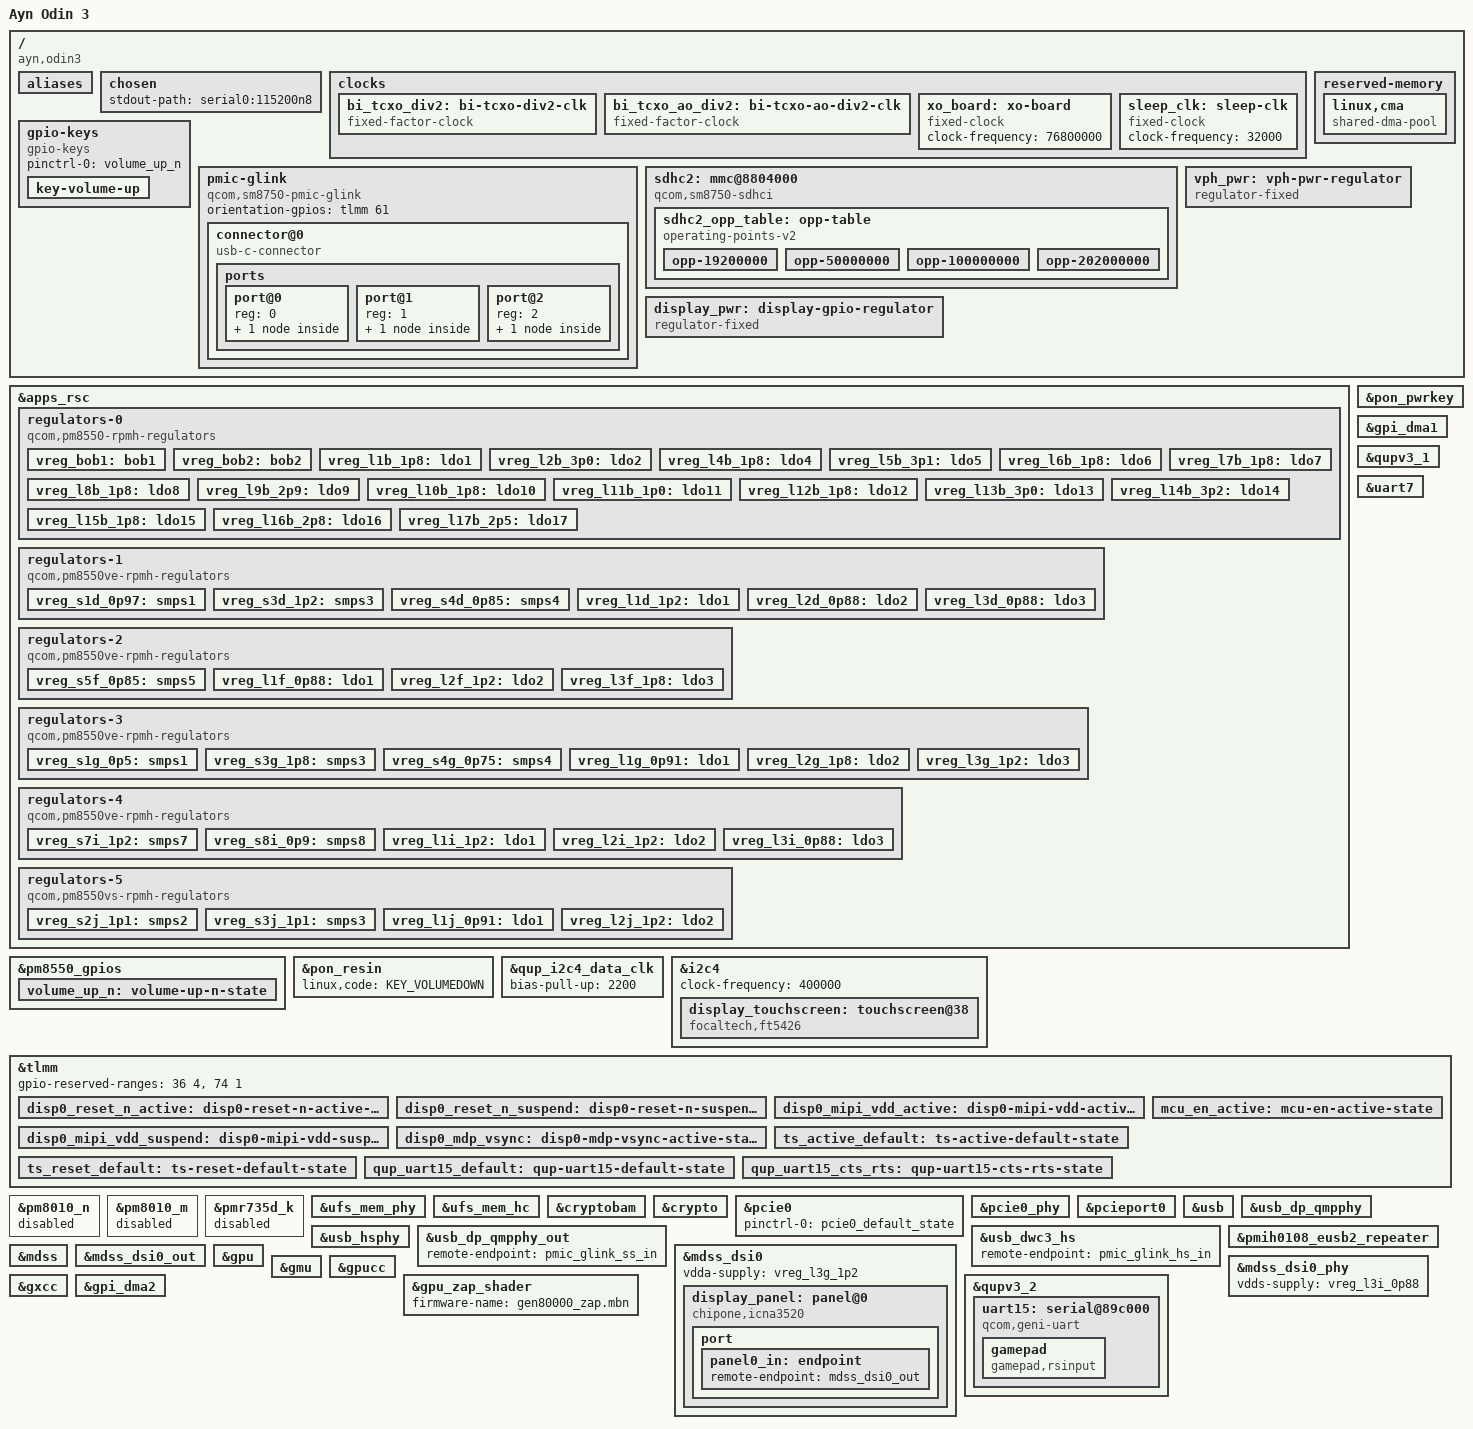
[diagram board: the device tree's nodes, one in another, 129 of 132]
// SPDX-License-Identifier: BSD-3-Clause
/*
 * Copyright (c) 2024 Qualcomm Innovation Center, Inc. All rights reserved.
 * Copyright (c) 2025 gio3k. All rights reserved.
 *
 * Device tree for the Ayn Odin 3, based on the sm8750-mtp dts
 * Takes some inspiration from sm8750-mainline
 */

/dts-v1/;

#include <dt-bindings/gpio/gpio.h>
#include <dt-bindings/leds/common.h>
#include <dt-bindings/regulator/qcom,rpmh-regulator.h>
#include "sm8750.dtsi"
#include "pm8010.dtsi"
#include "pm8550.dtsi"
#define PMK8550VE_SID 8
#include "pm8550ve.dtsi"
#include "pmih0108.dtsi"
#include "pmk8550.dtsi"
#include "pmr735d_a.dtsi"
#include "sm8750-pmics.dtsi"
#include "sm8750-mdss.dtsi"
#include "sm8750-gpu.dtsi"

/ {
	model = "Ayn Odin 3";
	compatible = "ayn,odin3", "qcom,sm8750";
	chassis-type = "handset";

	aliases {
		serial0 = &uart7;
		hsuart1 = &uart15;
	};

	chosen {
		stdout-path = "serial0:115200n8";	

		#address-cells = <2>;
		#size-cells = <2>;
		ranges;
	};

	clocks {
		bi_tcxo_div2: bi-tcxo-div2-clk {
			compatible = "fixed-factor-clock";
			#clock-cells = <0>;

			clocks = <&rpmhcc RPMH_CXO_CLK>;
			clock-mult = <1>;
			clock-div = <2>;
		};

		bi_tcxo_ao_div2: bi-tcxo-ao-div2-clk {
			compatible = "fixed-factor-clock";
			#clock-cells = <0>;

			clocks = <&rpmhcc RPMH_CXO_CLK_A>;
			clock-mult = <1>;
			clock-div = <2>;
		};

		xo_board: xo-board {
			compatible = "fixed-clock";
			clock-frequency = <76800000>;
			#clock-cells = <0>;
		};

		sleep_clk: sleep-clk {
			compatible = "fixed-clock";
			clock-frequency = <32000>;
			#clock-cells = <0>;
		};
	};

	gpio-keys {
		compatible = "gpio-keys";

		pinctrl-0 = <&volume_up_n>;
		pinctrl-names = "default";

		key-volume-up {
			label = "Volume Up";
			linux,code = <KEY_VOLUMEUP>;
			gpios = <&pm8550_gpios 6 GPIO_ACTIVE_LOW>;
			debounce-interval = <15>;
			linux,can-disable;
			wakeup-source;
		};
	};

	reserved-memory {
		#address-cells = <2>;
		#size-cells = <2>;

		linux,cma {
			compatible = "shared-dma-pool";
			size = <0x0 0x8000000>;
			reusable;
			linux,cma-default;
		};
	};

	pmic-glink {
		compatible = "qcom,sm8750-pmic-glink",
			     "qcom,sm8550-pmic-glink",
			     "qcom,pmic-glink";
		
		#address-cells = <1>;
		#size-cells = <0>;
		orientation-gpios = <&tlmm 61 GPIO_ACTIVE_HIGH>;

		connector@0 {
			compatible = "usb-c-connector";
			reg = <0>;
			power-role = "dual";
			data-role = "dual";

			ports {
				#address-cells = <1>;
				#size-cells = <0>;

				port@0 {
					reg = <0>;

					pmic_glink_hs_in: endpoint {
						remote-endpoint = <&usb_dwc3_hs>;
					};
				};

				port@1 {
					reg = <1>;

					pmic_glink_ss_in: endpoint {
						remote-endpoint = <&usb_dp_qmpphy_out>;
					};
				};

				port@2 {
					reg = <2>;

					pmic_glink_sbu: endpoint {};
				};
			};
		};
	};

	sdhc2: mmc@8804000 {
		compatible = "qcom,sm8750-sdhci", "qcom,sdhci-msm-v5";
		reg = <0 0x08804000 0 0x1000>;

		interrupts = <GIC_SPI 207 IRQ_TYPE_LEVEL_HIGH>,
			     <GIC_SPI 223 IRQ_TYPE_LEVEL_HIGH>;
		interrupt-names = "hc_irq", "pwr_irq";

		clocks = <&gcc GCC_SDCC2_AHB_CLK>,
			 <&gcc GCC_SDCC2_APPS_CLK>,
			 <&rpmhcc RPMH_CXO_CLK>;
		clock-names = "iface", "core", "xo";

		power-domains = <&rpmhpd RPMHPD_CX>;
		operating-points-v2 = <&sdhc2_opp_table>;

		interconnects = <&aggre2_noc MASTER_SDCC_2 QCOM_ICC_TAG_ALWAYS
				 &mc_virt SLAVE_EBI1 QCOM_ICC_TAG_ALWAYS>,
				<&gem_noc MASTER_APPSS_PROC QCOM_ICC_TAG_ACTIVE_ONLY
				 &config_noc SLAVE_SDCC_2 QCOM_ICC_TAG_ACTIVE_ONLY>;
		interconnect-names = "sdhc-ddr", "cpu-sdhc";

		iommus = <&apps_smmu 0x540 0>;

		bus-width = <4>;

		dma-coherent;

		sdhc2_opp_table: opp-table {
			compatible = "operating-points-v2";

			opp-19200000 {
				opp-hz = /bits/ 64 <19200000>;
				required-opps = <&rpmhpd_opp_min_svs>;
			};

			opp-50000000 {
				opp-hz = /bits/ 64 <50000000>;
				required-opps = <&rpmhpd_opp_low_svs>;
			};

			opp-100000000 {
				opp-hz = /bits/ 64 <100000000>;
				required-opps = <&rpmhpd_opp_svs>;
			};

			opp-202000000 {
				opp-hz = /bits/ 64 <202000000>;
				required-opps = <&rpmhpd_opp_svs_l1>;
			};
		};
	};

	vph_pwr: vph-pwr-regulator {
		compatible = "regulator-fixed";

		regulator-name = "vph_pwr";
		regulator-min-microvolt = <3600000>;
		regulator-max-microvolt = <3600000>;

		regulator-always-on;
		regulator-boot-on;
	};

	display_pwr: display-gpio-regulator {
		compatible = "regulator-fixed";

		regulator-name = "display_panel_avdd";
		regulator-min-microvolt = <5500000>;
		regulator-max-microvolt = <5500000>;
		regulator-enable-ramp-delay = <233>;

		gpio = <&pm8550_gpios 11 GPIO_ACTIVE_HIGH>;

		enable-active-high;
		regulator-always-on;
		regulator-boot-on;
	};
};

&apps_rsc {
	regulators-0 {
		compatible = "qcom,pm8550-rpmh-regulators";

		vdd-bob1-supply = <&vph_pwr>;
		vdd-bob2-supply = <&vph_pwr>;
		vdd-l1-l4-l10-supply = <&vreg_s3g_1p8>;
		vdd-l2-l13-l14-supply = <&vreg_bob1>;
		vdd-l3-supply = <&vreg_s7i_1p2>;
		vdd-l5-l16-supply = <&vreg_bob1>;
		vdd-l6-l7-supply = <&vreg_bob1>;
		vdd-l8-l9-supply = <&vreg_bob1>;
		vdd-l11-supply = <&vreg_s7i_1p2>;
		vdd-l12-supply = <&vreg_s3g_1p8>;
		vdd-l15-supply = <&vreg_s3g_1p8>;
		vdd-l17-supply = <&vreg_bob2>;

		qcom,pmic-id = "b";

		// RPMH_REGULATOR_MODE_RET = 1 in DTB (0 in header)
		// RPMH_REGULATOR_MODE_LPM = 2 in DTB
		// RPMH_REGULATOR_MODE_AUTO = 3 in DTB
		// RPMH_REGULATOR_MODE_HPM = 4 in DTB

		// rpmh-regulator-bobb1/regulator-pm-humu-bob1
		vreg_bob1: bob1 {
			// pm_humu_bob1
			regulator-name = "vreg_bob1";
			regulator-min-microvolt = <3008000>;
			regulator-max-microvolt = <4000000>;
			regulator-initial-mode = <RPMH_REGULATOR_MODE_HPM>;
		};

		// rpmh-regulator-bobb2/regulator-pm-humu-bob2
		vreg_bob2: bob2 {
			regulator-name = "vreg_bob2";
			regulator-min-microvolt = <2704000>;
			regulator-max-microvolt = <3008000>;
			regulator-initial-mode = <RPMH_REGULATOR_MODE_HPM>;
		};

		// rpmh-regulator-ldob1/regulator-pm-humu-l1
		vreg_l1b_1p8: ldo1 {
			// pm_humu_l1
			regulator-name = "vreg_l1b_1p8";
			regulator-min-microvolt = <1800000>;
			regulator-max-microvolt = <1800000>;
			regulator-initial-mode = <RPMH_REGULATOR_MODE_HPM>;
			regulator-allow-set-load;
			regulator-allowed-modes = <RPMH_REGULATOR_MODE_LPM RPMH_REGULATOR_MODE_HPM>;
		};

		// rpmh-regulator-ldob2/regulator-pm-humu-l2
		vreg_l2b_3p0: ldo2 {
			regulator-name = "vreg_l2b_3p0";
			regulator-min-microvolt = <3008000>;
			regulator-max-microvolt = <3048000>;
			regulator-initial-mode = <RPMH_REGULATOR_MODE_HPM>;
			regulator-allow-set-load;
			regulator-allowed-modes = <RPMH_REGULATOR_MODE_LPM RPMH_REGULATOR_MODE_HPM>;
		};

		// rpmh-regulator-ldob4/regulator-pm-humu-l4
		vreg_l4b_1p8: ldo4 {
			regulator-name = "vreg_l4b_1p8";
			regulator-min-microvolt = <1800000>;
			regulator-max-microvolt = <1800000>;
			regulator-initial-mode = <RPMH_REGULATOR_MODE_HPM>;
			regulator-allow-set-load;
			regulator-allowed-modes = <RPMH_REGULATOR_MODE_LPM RPMH_REGULATOR_MODE_HPM>;
		};

		// rpmh-regulator-ldob5/regulator-pm-humu-l5
		vreg_l5b_3p1: ldo5 {
			regulator-name = "vreg_l5b_3p1";
			regulator-min-microvolt = <3100000>;
			regulator-max-microvolt = <3148000>;
			regulator-initial-mode = <RPMH_REGULATOR_MODE_HPM>;
			regulator-allow-set-load;
			regulator-allowed-modes = <RPMH_REGULATOR_MODE_LPM RPMH_REGULATOR_MODE_HPM>;
		};

		// rpmh-regulator-ldob6/regulator-pm-humu-l6
		vreg_l6b_1p8: ldo6 {
			regulator-name = "vreg_l6b_1p8";
			regulator-min-microvolt = <1800000>;
			regulator-max-microvolt = <3008000>;
			regulator-initial-mode = <RPMH_REGULATOR_MODE_HPM>;
			regulator-allow-set-load;
			regulator-allowed-modes = <RPMH_REGULATOR_MODE_LPM RPMH_REGULATOR_MODE_HPM>;
		};

		// rpmh-regulator-ldob7/regulator-pm-humu-l7
		vreg_l7b_1p8: ldo7 {
			regulator-name = "vreg_l7b_1p8";
			regulator-min-microvolt = <1800000>;
			regulator-max-microvolt = <3008000>;
			regulator-initial-mode = <RPMH_REGULATOR_MODE_HPM>;
			regulator-allow-set-load;
			regulator-allowed-modes = <RPMH_REGULATOR_MODE_LPM RPMH_REGULATOR_MODE_HPM>;
		};

		// rpmh-regulator-ldob8/regulator-pm-humu-l8
		vreg_l8b_1p8: ldo8 {
			regulator-name = "vreg_l8b_1p8";
			regulator-min-microvolt = <1800000>;
			regulator-max-microvolt = <3008000>;
			regulator-initial-mode = <RPMH_REGULATOR_MODE_HPM>;
			regulator-allow-set-load;
			regulator-allowed-modes = <RPMH_REGULATOR_MODE_LPM RPMH_REGULATOR_MODE_HPM>;
		};

		// rpmh-regulator-ldob9/regulator-pm-humu-l9
		vreg_l9b_2p9: ldo9 {
			regulator-name = "vreg_l9b_2p9";
			regulator-min-microvolt = <2960000>;
			regulator-max-microvolt = <3008000>;
			regulator-initial-mode = <RPMH_REGULATOR_MODE_HPM>;
			regulator-allow-set-load;
			regulator-allowed-modes = <RPMH_REGULATOR_MODE_LPM RPMH_REGULATOR_MODE_HPM>;
		};

		// rpmh-regulator-ldob10/regulator-pm-humu-l10
		vreg_l10b_1p8: ldo10 {
			regulator-name = "vreg_l10b_1p8";
			regulator-min-microvolt = <1800000>;
			regulator-max-microvolt = <1800000>;
			regulator-initial-mode = <RPMH_REGULATOR_MODE_HPM>;
			regulator-allow-set-load;
			regulator-allowed-modes = <RPMH_REGULATOR_MODE_LPM RPMH_REGULATOR_MODE_HPM>;
		};

		// rpmh-regulator-ldob11/regulator-pm-humu-l11
		vreg_l11b_1p0: ldo11 {
			regulator-name = "vreg_l11b_1p0";
			regulator-min-microvolt = <1064000>;
			regulator-max-microvolt = <1292000>;
			regulator-initial-mode = <RPMH_REGULATOR_MODE_HPM>;
			regulator-allow-set-load;
			regulator-allowed-modes = <RPMH_REGULATOR_MODE_LPM RPMH_REGULATOR_MODE_HPM>;
		};

		// rpmh-regulator-ldob12/regulator-pm-humu-l12
		vreg_l12b_1p8: ldo12 {
			regulator-name = "vreg_l12b_1p8";
			regulator-min-microvolt = <1800000>;
			regulator-max-microvolt = <1800000>;
			regulator-initial-mode = <RPMH_REGULATOR_MODE_HPM>;
			regulator-allow-set-load;
			regulator-allowed-modes = <RPMH_REGULATOR_MODE_LPM RPMH_REGULATOR_MODE_HPM>;
			regulator-always-on;
		};

		// rpmh-regulator-ldob13/regulator-pm-humu-l13
		vreg_l13b_3p0: ldo13 {
			regulator-name = "vreg_l13b_3p0";
			regulator-min-microvolt = <3000000>;
			regulator-max-microvolt = <3000000>;
			regulator-initial-mode = <RPMH_REGULATOR_MODE_HPM>;
			regulator-allow-set-load;
			regulator-allowed-modes = <RPMH_REGULATOR_MODE_LPM RPMH_REGULATOR_MODE_HPM>;
		};

		// rpmh-regulator-ldob14/regulator-pm-humu-l14
		vreg_l14b_3p2: ldo14 {
			regulator-name = "vreg_l14b_3p2";
			regulator-min-microvolt = <3200000>;
			regulator-max-microvolt = <3200000>;
			regulator-initial-mode = <RPMH_REGULATOR_MODE_HPM>;
			regulator-allow-set-load;
			regulator-allowed-modes = <RPMH_REGULATOR_MODE_LPM RPMH_REGULATOR_MODE_HPM>;
		};

		// rpmh-regulator-ldob15/regulator-pm-humu-l15
		vreg_l15b_1p8: ldo15 {
			regulator-name = "vreg_l15b_1p8";
			regulator-min-microvolt = <1800000>;
			regulator-max-microvolt = <1800000>;
			regulator-initial-mode = <RPMH_REGULATOR_MODE_HPM>;
			regulator-allow-set-load;
			regulator-allowed-modes = <RPMH_REGULATOR_MODE_LPM RPMH_REGULATOR_MODE_HPM>;
			regulator-always-on;
		};

		// rpmh-regulator-ldob16/regulator-pm-humu-l16
		vreg_l16b_2p8: ldo16 {
			regulator-name = "vreg_l16b_2p8";
			regulator-min-microvolt = <2800000>;
			regulator-max-microvolt = <2800000>;
			regulator-initial-mode = <RPMH_REGULATOR_MODE_HPM>;
			regulator-allow-set-load;
			regulator-allowed-modes = <RPMH_REGULATOR_MODE_LPM RPMH_REGULATOR_MODE_HPM>;
		};

		// rpmh-regulator-ldob17/regulator-pm-humu-l17
		vreg_l17b_2p5: ldo17 {
			regulator-name = "vreg_l17b_2p5";
			regulator-min-microvolt = <2504000>;
			regulator-max-microvolt = <2504000>;
			regulator-initial-mode = <RPMH_REGULATOR_MODE_HPM>;
			regulator-allow-set-load;
			regulator-allowed-modes = <RPMH_REGULATOR_MODE_LPM RPMH_REGULATOR_MODE_HPM>;
		};
	};

	regulators-1 {
		compatible = "qcom,pm8550ve-rpmh-regulators";

		vdd-l1-supply = <&vreg_s7i_1p2>;
		vdd-l2-supply = <&vreg_s1d_0p97>;
		vdd-l3-supply = <&vreg_s1d_0p97>;
		vdd-s1-supply = <&vph_pwr>;
		vdd-s3-supply = <&vph_pwr>;
		vdd-s4-supply = <&vph_pwr>;

		qcom,pmic-id = "d";

		// rpmh-regulator-smpd1/regulator-pm-v8d-s1
		vreg_s1d_0p97: smps1 {
			regulator-name = "vreg_s1d_0p97";
			regulator-min-microvolt = <880000>;
			regulator-max-microvolt = <1100000>;
			regulator-initial-mode = <RPMH_REGULATOR_MODE_HPM>;
		};

		// rpmh-regulator-smpd3/regulator-pm-v8d-s3
		vreg_s3d_1p2: smps3 {
			regulator-name = "vreg_s3d_1p2";
			regulator-min-microvolt = <1200000>;
			regulator-max-microvolt = <1300000>;
			regulator-initial-mode = <RPMH_REGULATOR_MODE_HPM>;
		};

		// rpmh-regulator-smpd4/regulator-pm-v8d-s4
		vreg_s4d_0p85: smps4 {
			regulator-name = "vreg_s4d_0p85";
			regulator-min-microvolt = <500000>;
			regulator-max-microvolt = <1036000>;
			regulator-initial-mode = <RPMH_REGULATOR_MODE_HPM>;
		};

		// rpmh-regulator-ldod1/regulator-pm-v8d-l1
		vreg_l1d_1p2: ldo1 {
			regulator-name = "vreg_l1d_1p2";
			regulator-min-microvolt = <1200000>;
			regulator-max-microvolt = <1200000>;
			regulator-initial-mode = <RPMH_REGULATOR_MODE_HPM>;
			regulator-allow-set-load;
			regulator-allowed-modes = <RPMH_REGULATOR_MODE_LPM RPMH_REGULATOR_MODE_HPM>;
		};

		// rpmh-regulator-ldod2/regulator-pm-v8d-l2
		vreg_l2d_0p88: ldo2 {
			regulator-name = "vreg_l2d_0p88";
			regulator-min-microvolt = <880000>;
			regulator-max-microvolt = <912000>;
			regulator-initial-mode = <RPMH_REGULATOR_MODE_HPM>;
			regulator-allow-set-load;
			regulator-allowed-modes = <RPMH_REGULATOR_MODE_LPM RPMH_REGULATOR_MODE_HPM>;
		};

		// rpmh-regulator-ldod3/regulator-pm-v8d-l3
		vreg_l3d_0p88: ldo3 {
			regulator-name = "vreg_l3d_0p88";
			regulator-min-microvolt = <880000>;
			regulator-max-microvolt = <920000>;
			regulator-initial-mode = <RPMH_REGULATOR_MODE_HPM>;
			regulator-allow-set-load;
			regulator-allowed-modes = <RPMH_REGULATOR_MODE_LPM RPMH_REGULATOR_MODE_HPM>;
		};
	};

	regulators-2 {
		compatible = "qcom,pm8550ve-rpmh-regulators";

		vdd-l1-supply = <&vreg_s1d_0p97>;
		vdd-l2-supply = <&vreg_s7i_1p2>;
		vdd-l3-supply = <&vreg_s3g_1p8>;
		vdd-s5-supply = <&vph_pwr>;

		qcom,pmic-id = "f";

		// rpmh-regulator-smpf5/regulator-pm-v8f-s5
		vreg_s5f_0p85: smps5 {
			regulator-name = "vreg_s5f_0p85";
			regulator-min-microvolt = <500000>;
			regulator-max-microvolt = <1000000>;
			regulator-initial-mode = <RPMH_REGULATOR_MODE_HPM>;
		};

		// rpmh-regulator-ldof1/regulator-pm-vxf-l1
		// todo: -ao & -so
		vreg_l1f_0p88: ldo1 {
			regulator-name = "vreg_l1f_0p88";
			regulator-min-microvolt = <880000>;
			regulator-max-microvolt = <920000>;
			regulator-initial-mode = <RPMH_REGULATOR_MODE_HPM>;
			regulator-allow-set-load;
			regulator-allowed-modes = <RPMH_REGULATOR_MODE_LPM RPMH_REGULATOR_MODE_HPM>;
		};

		// rpmh-regulator-ldof2/regulator-pm-vxf-l2
		vreg_l2f_1p2: ldo2 {
			regulator-name = "vreg_l2f_1p2";
			regulator-min-microvolt = <1200000>;
			regulator-max-microvolt = <1200000>;
			regulator-initial-mode = <RPMH_REGULATOR_MODE_HPM>;
			regulator-allow-set-load;
			regulator-allowed-modes = <RPMH_REGULATOR_MODE_LPM RPMH_REGULATOR_MODE_HPM>;
		};

		// rpmh-regulator-ldof3/regulator-pm-vxf-l3
		vreg_l3f_1p8: ldo3 {
			regulator-name = "vreg_l3f_1p8";
			regulator-min-microvolt = <1800000>;
			regulator-max-microvolt = <1800000>;
			regulator-initial-mode = <RPMH_REGULATOR_MODE_HPM>;
			regulator-allow-set-load;
			regulator-allowed-modes = <RPMH_REGULATOR_MODE_LPM RPMH_REGULATOR_MODE_HPM>;
		};
	};

	regulators-3 {
		compatible = "qcom,pm8550ve-rpmh-regulators";

		vdd-l1-supply = <&vreg_s1d_0p97>;
		vdd-l2-supply = <&vreg_s3g_1p8>;
		vdd-l3-supply = <&vreg_s7i_1p2>;
		vdd-s1-supply = <&vph_pwr>;
		vdd-s3-supply = <&vph_pwr>;

		qcom,pmic-id = "g";

		// rpmh-regulator-smpg1/regulator-pm-v8g-s1
		vreg_s1g_0p5: smps1 {
			regulator-name = "vreg_s1g_0p5";
			regulator-min-microvolt = <300000>;
			regulator-max-microvolt = <700000>;
			regulator-initial-mode = <RPMH_REGULATOR_MODE_HPM>;
		};

		// rpmh-regulator-smpg3/regulator-pm-v8g-s3
		vreg_s3g_1p8: smps3 {
			regulator-name = "vreg_s3g_1p8";
			regulator-min-microvolt = <1856000>;
			regulator-max-microvolt = <2000000>;
			regulator-initial-mode = <RPMH_REGULATOR_MODE_LPM>;
			regulator-allow-set-load;
			regulator-allowed-modes = <RPMH_REGULATOR_MODE_LPM RPMH_REGULATOR_MODE_HPM>;
		};

		// rpmh-regulator-smpg4/regulator-pm-v8g-s4
		vreg_s4g_0p75: smps4 {
			regulator-name = "vreg_s4g_0p75";
			regulator-min-microvolt = <300000>;
			regulator-max-microvolt = <900000>;
			regulator-initial-mode = <RPMH_REGULATOR_MODE_HPM>;
		};

		// rpmh-regulator-ldog1/regulator-pm-v8g-l1
		vreg_l1g_0p91: ldo1 {
			regulator-name = "vreg_l1g_0p91";
			regulator-min-microvolt = <912000>;
			regulator-max-microvolt = <936000>;
			regulator-initial-mode = <RPMH_REGULATOR_MODE_HPM>;
			regulator-allow-set-load;
			regulator-allowed-modes = <RPMH_REGULATOR_MODE_LPM RPMH_REGULATOR_MODE_HPM>;
		};

		// rpmh-regulator-ldog2/regulator-pm-v8g-s2
		vreg_l2g_1p8: ldo2 {
			regulator-name = "vreg_l2g_1p8";
			regulator-min-microvolt = <1200000>;
			regulator-max-microvolt = <1860000>;
			regulator-initial-mode = <RPMH_REGULATOR_MODE_HPM>;
			regulator-allow-set-load;
			regulator-allowed-modes = <RPMH_REGULATOR_MODE_LPM RPMH_REGULATOR_MODE_HPM>;
		};

		// rpmh-regulator-ldog3/regulator-pm-v8g-l3
		vreg_l3g_1p2: ldo3 {
			regulator-name = "vreg_l3g_1p2";
			regulator-min-microvolt = <1200000>;
			regulator-max-microvolt = <1256000>;
			regulator-initial-mode = <RPMH_REGULATOR_MODE_HPM>;
			regulator-allow-set-load;
			regulator-allowed-modes = <RPMH_REGULATOR_MODE_LPM RPMH_REGULATOR_MODE_HPM>;
		};
	};

	regulators-4 {
		compatible = "qcom,pm8550ve-rpmh-regulators";

		vdd-l1-supply = <&vreg_s7i_1p2>;
		vdd-l2-supply = <&vreg_s7i_1p2>;
		vdd-l3-supply = <&vreg_s1d_0p97>;
		vdd-s7-supply = <&vph_pwr>;
		vdd-s8-supply = <&vph_pwr>;

		qcom,pmic-id = "i";

		// rpmh-regulator-smpi7/regulator-pm-v8i-s7
		vreg_s7i_1p2: smps7 {
			regulator-name = "vreg_s7i_1p2";
			regulator-min-microvolt = <1224000>;
			regulator-max-microvolt = <1340000>;
			regulator-initial-mode = <RPMH_REGULATOR_MODE_HPM>;
		};

		// rpmh-regulator-smpi8/regulator-pm-v8i-s8
		vreg_s8i_0p9: smps8 {
			regulator-name = "vreg_s8i_0p9";
			regulator-min-microvolt = <900000>;
			regulator-max-microvolt = <972000>;
			regulator-initial-mode = <RPMH_REGULATOR_MODE_HPM>;
		};

		// rpmh-regulator-ldoi1/regulator-pm-v8i-l1
		vreg_l1i_1p2: ldo1 {
			regulator-name = "vreg_l1i_1p2";
			regulator-min-microvolt = <1200000>;
			regulator-max-microvolt = <1200000>;
			regulator-initial-mode = <RPMH_REGULATOR_MODE_HPM>;
			regulator-allow-set-load;
			regulator-allowed-modes = <RPMH_REGULATOR_MODE_LPM RPMH_REGULATOR_MODE_HPM>;
		};

		// rpmh-regulator-ldoi2/regulator-pm-v8i-l2
		vreg_l2i_1p2: ldo2 {
			regulator-name = "vreg_l2i_1p2";
			regulator-min-microvolt = <1200000>;
			regulator-max-microvolt = <1200000>;
			regulator-initial-mode = <RPMH_REGULATOR_MODE_HPM>;
			regulator-allow-set-load;
			regulator-allowed-modes = <RPMH_REGULATOR_MODE_LPM RPMH_REGULATOR_MODE_HPM>;
		};

		// rpmh-regulator-ldoi3/regulator-pm-v8i-l3
		vreg_l3i_0p88: ldo3 {
			regulator-name = "vreg_l3i_0p88";
			regulator-min-microvolt = <880000>;
			regulator-max-microvolt = <912000>;
			regulator-initial-mode = <RPMH_REGULATOR_MODE_HPM>;
			regulator-allow-set-load;
			regulator-allowed-modes = <RPMH_REGULATOR_MODE_LPM RPMH_REGULATOR_MODE_HPM>;
		};
	};

	regulators-5 {
		compatible = "qcom,pm8550vs-rpmh-regulators";

		vdd-l1-supply = <&vreg_s1d_0p97>;
		vdd-l2-supply = <&vreg_s7i_1p2>;
		vdd-s2-supply = <&vph_pwr>;
		vdd-s3-supply = <&vph_pwr>;

		qcom,pmic-id = "j";

		// rpmh-regulator-smpj2/regulator-pm-v6j-s2
		vreg_s2j_1p1: smps2 {
			regulator-name = "vreg_s2j_1p1";
			regulator-min-microvolt = <1000000>;
			regulator-max-microvolt = <1100000>;
			regulator-initial-mode = <RPMH_REGULATOR_MODE_HPM>;
		};

		// rpmh-regulator-smpj3/regulator-pm-v6j-s3
		vreg_s3j_1p1: smps3 {
			regulator-name = "vreg_s3j_1p1";
			regulator-min-microvolt = <1000000>;
			regulator-max-microvolt = <1100000>;
			regulator-initial-mode = <RPMH_REGULATOR_MODE_HPM>;
		};

		// rpmh-regulator-ldoj1/regulator-pm-v6j-l1
		vreg_l1j_0p91: ldo1 {
			regulator-name = "vreg_l1j_0p91";
			regulator-min-microvolt = <880000>;
			regulator-max-microvolt = <920000>;
			regulator-initial-mode = <RPMH_REGULATOR_MODE_HPM>;
			regulator-allow-set-load;
			regulator-allowed-modes = <RPMH_REGULATOR_MODE_LPM RPMH_REGULATOR_MODE_HPM>;
		};

		// rpmh-regulator-ldoj2/regulator-pm-v6j-l2
		vreg_l2j_1p2: ldo2 {
			regulator-name = "vreg_l2j_1p2";
			regulator-min-microvolt = <1200000>;
			regulator-max-microvolt = <1200000>;
			regulator-initial-mode = <RPMH_REGULATOR_MODE_HPM>;
			regulator-allow-set-load;
			regulator-allowed-modes = <RPMH_REGULATOR_MODE_LPM RPMH_REGULATOR_MODE_HPM>;
		};
	};
};

/* Power & volume keys */
&pm8550_gpios {
	volume_up_n: volume-up-n-state {
		pins = "gpio6";
		function = "normal";
		input-enable;
		bias-pull-up;
		power-source = <1>;
	};
};

&pon_pwrkey {
	status = "okay";
};

&pon_resin {
	status = "okay";

	linux,code = <KEY_VOLUMEDOWN>;
};

// I2C through QUPv3_1
&gpi_dma1 {
	status = "okay";
};

&qupv3_1 {
	status = "okay";
};

&uart7 {
	status = "okay";
};

&qup_i2c4_data_clk {
	/* Use internal I2C pull-up */
	bias-pull-up = <2200>;
};

&i2c4 {
	status = "okay";

	clock-frequency = <400000>;

	// i2c@a90000 / focaltech@38
	display_touchscreen: touchscreen@38 {
		status = "okay";
		reg = <0x38>;
		compatible = "focaltech,ft5426";

		no-regmap-bulk-read;
		
		interrupts-extended = <&tlmm 162 IRQ_TYPE_EDGE_FALLING>;
		reset-gpios = <&tlmm 161 GPIO_ACTIVE_LOW>;

		vcc-supply = <&vreg_l14b_3p2>;
		iovcc-supply = <&vreg_l12b_1p8>;

		touchscreen-size-x = <1080>;
		touchscreen-size-y = <1920>;

		pinctrl-0 = <&ts_reset_default &ts_active_default>;
		pinctrl-names = "default";
	};
};

&tlmm {
	/* reserved for secure world */
	gpio-reserved-ranges = <36 4>, <74 1>;

	// Display GPIOs
	disp0_reset_n_active: disp0-reset-n-active-state {
		pins = "gpio98";
		function = "gpio";
		drive-strength = <8>;
		bias-disable = <0>;
	};

	disp0_reset_n_suspend: disp0-reset-n-suspend-state {
		pins = "gpio98";
		function = "gpio";
		drive-strength = <2>;
		bias-pull-down;
	};

	disp0_mipi_vdd_active: disp0-mipi-vdd-active-state {
		pins = "gpio97";
		function = "gpio";
		drive-strength = <8>;
		bias-disable = <0>;
	};

	disp0_mipi_vdd_suspend: disp0-mipi-vdd-suspend-state {
		pins = "gpio97";
		function = "gpio";
		drive-strength = <2>;
		bias-pull-down;
	};

	disp0_mdp_vsync: disp0-mdp-vsync-active-state {
		pins = "gpio86";
		function = "mdp_vsync";
		drive-strength = <2>;
		bias-pull-down;
	};

	// Touchscreen GPIOs
	// pmx_ts_active / ts_active
	ts_active_default: ts-active-default-state {
		pins = "gpio162";
		function = "gpio";
		drive-strength = <8>;
		bias-pull-up;
	};

	// pmx_ts_release / ts_release
	ts_reset_default: ts-reset-default-state {
		pins = "gpio161";
		function = "gpio";
		drive-strength = <2>;
		bias-disable;
	};

	// MCU (secondary chip on Retroid / AYN devices, handles input) GPIOs
	mcu_en_active: mcu-en-active-state {
		pins = "gpio83";
		function = "gpio";
		drive-strength = <2>;
		bias-pull-down;
	};

	qup_uart15_default: qup-uart15-default-state {
		/* TX, RX */
		pins = "gpio30", "gpio31";
		function = "qup2_se7";
		drive-strength = <2>;
		bias-disable;
	};

	qup_uart15_cts_rts: qup-uart15-cts-rts-state {
		/* CTS, RTS */
		pins = "gpio28", "gpio29";
		function = "qup2_se7";
		drive-strength = <2>;
		bias-pull-down;
	};
};

/* Disabled features */
// Mostly regulators that don't exist on the Odin 3
// pm8010@d is disabled
&pm8010_n {
	status = "disabled";
};

// pm8010@c is disabled
&pm8010_m {
	status = "disabled";
};

// pmr735d@a is disabled
&pmr735d_k {
	status = "disabled";
};

/* UFS */
&ufs_mem_phy {
	vdda-phy-supply = <&vreg_l1j_0p91>;
	vdda-pll-supply = <&vreg_l3g_1p2>;

	status = "okay";
};

&ufs_mem_hc {
	reset-gpios = <&tlmm 215 GPIO_ACTIVE_LOW>;

	vcc-supply = <&vreg_l17b_2p5>;
	vcc-max-microamp = <1300000>;
	vccq-supply = <&vreg_l1d_1p2>; 
	vccq-max-microamp = <1200000>;

	status = "okay";
};

/* Crypto (QCE) */
&cryptobam {
	status = "okay";
};

&crypto {
	status = "okay";
};

/* PCIe */
&pcie0 {
	status = "okay";

	pinctrl-0 = <&pcie0_default_state>;
	pinctrl-names = "default";
};

&pcie0_phy {
	status = "okay";

	vdda-phy-supply = <&vreg_l1f_0p88>;
	vdda-pll-supply = <&vreg_l3g_1p2>;
};

&pcieport0 {
	status = "okay";

	wake-gpios = <&tlmm 104 GPIO_ACTIVE_HIGH>;
	reset-gpios = <&tlmm 102 GPIO_ACTIVE_LOW>;
};

/* USB */
&usb {
	status = "okay";
};

&usb_dp_qmpphy {
	status = "okay";

	vdda-pll-supply = <&vreg_l2d_0p88>;
	vdda-phy-supply = <&vreg_l3g_1p2>;
};

&usb_hsphy {
	status = "okay";

	vdd-supply = <&vreg_l2d_0p88>; // pm-v8d-l2
	vdda12-supply = <&vreg_l3g_1p2>; // pm-v8g-l3

	phys = <&pmih0108_eusb2_repeater>;
};

&usb_dp_qmpphy_out {
	remote-endpoint = <&pmic_glink_ss_in>;
};

&usb_dwc3_hs {
	remote-endpoint = <&pmic_glink_hs_in>;
};

&pmih0108_eusb2_repeater {
	status = "okay";

	vdd18-supply = <&vreg_l15b_1p8>; // pm-humu-l15
	vdd3-supply = <&vreg_l5b_3p1>; // pm-humu-l5
};

/* MDSS */
&mdss {
	status = "okay";
};

&mdss_dsi0 {
	status = "okay";
	
	vdda-supply = <&vreg_l3g_1p2>;

	display_panel: panel@0 {
		reg = <0>;
		compatible = "chipone,icna3520";
		
		reset-gpios = <&tlmm 98 GPIO_ACTIVE_HIGH>;

		vddio-supply = <&vreg_l12b_1p8>;
		vci-supply = <&vreg_l13b_3p0>;
		vdd-supply = <&vreg_l11b_1p0>;
		rotation = <90>;
		
		pinctrl-0 = <&disp0_reset_n_active>, <&disp0_mdp_vsync>;
		pinctrl-1 = <&disp0_reset_n_suspend>, <&disp0_mdp_vsync>;
		pinctrl-names = "default", "sleep";

		port {
			panel0_in: endpoint {
				remote-endpoint = <&mdss_dsi0_out>;
			};
		};
	};
};

&mdss_dsi0_out {
	remote-endpoint = <&panel0_in>;
	data-lanes = <0 1 2 3>;
};

&mdss_dsi0_phy {
	status = "okay";
	vdds-supply = <&vreg_l3i_0p88>;
};

/* GPU */
&gpu {
	status = "okay";
};

&gmu {
	status = "okay";
};

&gpucc {
	status = "okay";
};

&gxcc {
	status = "okay";
};

&gpu_zap_shader {
	firmware-name = "gen80000_zap.mbn";
};

/* Gamepad / RSInput */
&gpi_dma2 {
	status = "okay";
};

// The base DTSI doesn't have a UART15 (this seems to be something Ayn does)
// The gamepad needs it, so we add our own here
&qupv3_2 {
	status = "okay";

	uart15: serial@89c000 {
		status = "okay";

		compatible = "qcom,geni-uart";
		reg = <0x0 0x0089c000 0x0 0x4000>;

		interrupts = <GIC_SPI 462 IRQ_TYPE_LEVEL_HIGH>;

		clocks = <&gcc GCC_QUPV3_WRAP2_S7_CLK>;
		clock-names = "se";

		interconnects = <&clk_virt MASTER_QUP_CORE_2 QCOM_ICC_TAG_ALWAYS
				 &clk_virt SLAVE_QUP_CORE_2 QCOM_ICC_TAG_ALWAYS>,
				<&gem_noc MASTER_APPSS_PROC QCOM_ICC_TAG_ALWAYS
				 &config_noc SLAVE_QUP_2 QCOM_ICC_TAG_ALWAYS>;
		interconnect-names = "qup-core",
				     "qup-config";

		pinctrl-0 = <&qup_uart15_default>;
		pinctrl-names = "default";
		
		gamepad {
			compatible = "gamepad,rsinput";

			gamepad-name = "AYN Odin3 Gamepad";
			gamepad-bus = <0x0003>;
			gamepad-vid = <0x2020>;
			gamepad-pid = <0x3001>;
			gamepad-rev = <0x0001>;

			vdd-supply = <&vreg_bob2>;

			// rs_gpio_request requests gpio595 & gpio597 (gpio83 and gpio85)
			// gpio83 is usually used for &i2c_hub_7 (it's qupv3_hub_i2c7_scl_active downstream)
			// The Odin 3 has i2c_hub_7 disabled and seems to use gpio83 for the MCU
			enable-gpios = <&tlmm 85 GPIO_ACTIVE_HIGH>;
			boot-gpios = <&tlmm 83 GPIO_ACTIVE_LOW>; 
			pinctrl-0 = <&mcu_en_active>;
			pinctrl-names = "default";
		};
	};
};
